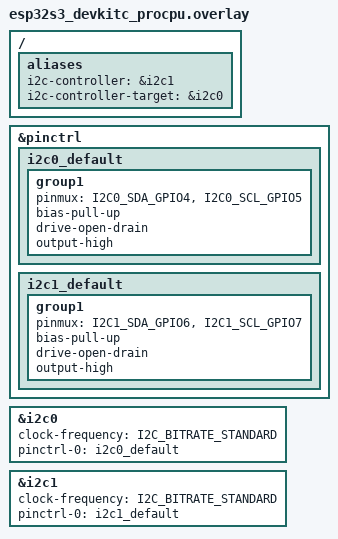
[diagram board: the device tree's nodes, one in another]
/*
 * Copyright (c) 2026 Espressif Systems (Shanghai) Co., Ltd.
 *
 * SPDX-License-Identifier: Apache-2.0
 *
 * External-loopback overlay for the i2c rtio_loopback sample.
 *
 * Wire up two physical jumpers on the devkit:
 *   GPIO4 (i2c0 SDA) <-> GPIO6 (i2c1 SDA)
 *   GPIO5 (i2c0 SCL) <-> GPIO7 (i2c1 SCL)
 */

/ {
	aliases {
		i2c-controller = &i2c1;
		i2c-controller-target = &i2c0;
	};
};

&pinctrl {
	i2c0_default: i2c0_default {
		group1 {
			pinmux = <I2C0_SDA_GPIO4>,
				 <I2C0_SCL_GPIO5>;
			bias-pull-up;
			drive-open-drain;
			output-high;
		};
	};

	i2c1_default: i2c1_default {
		group1 {
			pinmux = <I2C1_SDA_GPIO6>,
				 <I2C1_SCL_GPIO7>;
			bias-pull-up;
			drive-open-drain;
			output-high;
		};
	};
};

&i2c0 {
	status = "okay";
	clock-frequency = <I2C_BITRATE_STANDARD>;
	pinctrl-0 = <&i2c0_default>;
	pinctrl-names = "default";
};

&i2c1 {
	status = "okay";
	clock-frequency = <I2C_BITRATE_STANDARD>;
	pinctrl-0 = <&i2c1_default>;
	pinctrl-names = "default";
};
